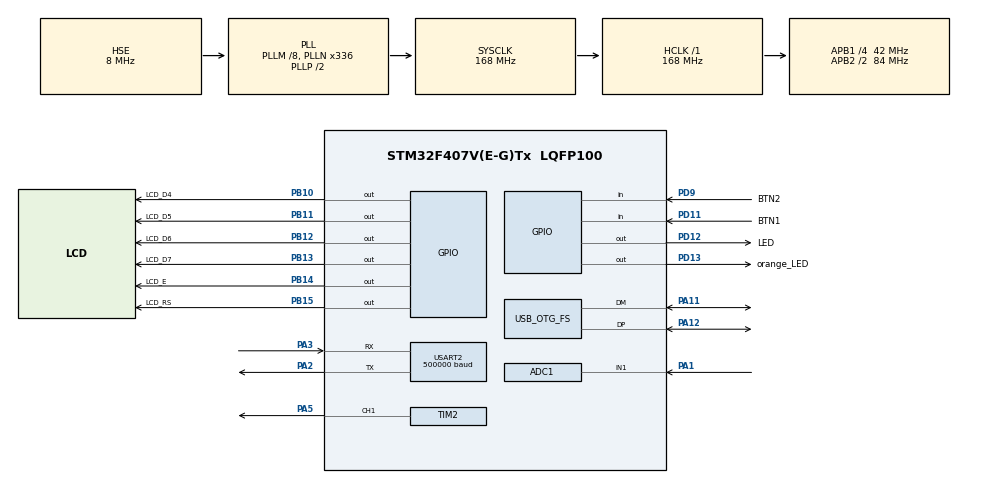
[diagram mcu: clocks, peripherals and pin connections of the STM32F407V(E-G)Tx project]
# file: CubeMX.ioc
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ADC1.Channel-1\#ChannelRegularConversion=ADC_CHANNEL_1
ADC1.NbrOfConversionFlag=1
ADC1.Rank-1\#ChannelRegularConversion=1
ADC1.SamplingTime-1\#ChannelRegularConversion=ADC_SAMPLETIME_3CYCLES
ADC1.master=1
FREERTOS.Tasks01=defaultTask,24,128,StartDefaultTask,Default,NULL,Dynamic,NULL,NULL
Mcu.Family=STM32F4
Mcu.Name=STM32F407V(E-G)Tx
Mcu.Package=LQFP100
NVIC.PriorityGroup=NVIC_PRIORITYGROUP_4
NVIC.TIM7_IRQn=true\:15\:0\:false\:false\:true\:false\:false\:true\:true
NVIC.TimeBase=TIM7_IRQn
NVIC.TimeBaseIP=TIM7
PA1.Signal=ADCx_IN1
PA11.Mode=Device_Only
PA11.Signal=USB_OTG_FS_DM
PA12.Mode=Device_Only
PA12.Signal=USB_OTG_FS_DP
PA2.Mode=Asynchronous
PA2.Signal=USART2_TX
PA3.Mode=Asynchronous
PA3.Signal=USART2_RX
PA5.Signal=S_TIM2_CH1_ETR
PB10.GPIO_Label=LCD_D4
PB10.Signal=GPIO_Output
PB11.GPIO_Label=LCD_D5
PB11.Signal=GPIO_Output
PB12.GPIO_Label=LCD_D6
PB12.Signal=GPIO_Output
PB13.GPIO_Label=LCD_D7
PB13.Signal=GPIO_Output
PB14.GPIO_Label=LCD_E
PB14.Signal=GPIO_Output
PB15.GPIO_Label=LCD_RS
PB15.Signal=GPIO_Output
PD11.GPIO_Label=BTN1
PD11.GPIO_PuPd=GPIO_PULLUP
PD11.Signal=GPIO_Input
PD12.GPIO_Label=LED
PD12.Signal=GPIO_Output
PD13.GPIO_Label=orange_LED
PD13.Signal=GPIO_Output
PD9.GPIO_Label=BTN2
PD9.GPIO_PuPd=GPIO_PULLUP
PD9.Signal=GPIO_Input
PH0-OSC_IN.Mode=HSE-External-Oscillator
PH0-OSC_IN.Signal=RCC_OSC_IN
PH1-OSC_OUT.Mode=HSE-External-Oscillator
PH1-OSC_OUT.Signal=RCC_OSC_OUT
ProjectManager.HeapSize=0x200
ProjectManager.StackSize=0x400
ProjectManager.TargetToolchain=CMake
RCC.48MHZClocksFreq_Value=48000000
RCC.AHBFreq_Value=168000000
RCC.APB1CLKDivider=RCC_HCLK_DIV4
RCC.APB1Freq_Value=42000000
RCC.APB1TimFreq_Value=84000000
RCC.APB2CLKDivider=RCC_HCLK_DIV2
RCC.APB2Freq_Value=84000000
RCC.APB2TimFreq_Value=168000000
RCC.CortexFreq_Value=168000000
RCC.HCLKFreq_Value=168000000
RCC.HSE_VALUE=8000000
RCC.HSI_VALUE=16000000
RCC.LSE_VALUE=32768
RCC.PLLM=8
RCC.PLLN=336
RCC.PLLQ=7
RCC.SYSCLKFreq_VALUE=168000000
RCC.SYSCLKSource=RCC_SYSCLKSOURCE_PLLCLK
RCC.VCOOutputFreq_Value=336000000
SH.ADCx_IN1.0=ADC1_IN1,IN1
SH.S_TIM2_CH1_ETR.0=TIM2_CH1,PWM Generation1 CH1
TIM2.AutoReloadPreload=TIM_AUTORELOAD_PRELOAD_ENABLE
TIM2.Channel-PWM\ Generation1\ CH1=TIM_CHANNEL_1
TIM2.Period=19999
TIM2.Prescaler=83
TIM3.Prescaler=83
USART2.BaudRate=500000
USART2.VirtualMode=VM_ASYNC
USB_OTG_FS.VirtualMode=Device_Only
VP_FREERTOS_VS_CMSIS_V2.Mode=CMSIS_V2
VP_SYS_VS_tim7.Mode=TIM7
VP_TIM3_VS_ClockSourceINT.Mode=Internal
board=custom

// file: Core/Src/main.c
/* USER CODE BEGIN Header */
/**
 ******************************************************************************
 * @file           : main.c
 * @brief          : Main program body
 ******************************************************************************
 * @attention
 *
 * Copyright (c) 2026 STMicroelectronics.
 * All rights reserved.
 *
 * This software is licensed under terms that can be found in the LICENSE file
 * in the root directory of this software component.
 * If no LICENSE file comes with this software, it is provided AS-IS.
 *
 ******************************************************************************
 */
/* USER CODE END Header */
#include "main.h"
#include "cmsis_os.h"

/* USER CODE BEGIN Includes */
#include "logger/itm.h"
#include "main_app.h"
#include "usb/usb_app.h"
/* USER CODE END Includes */

ADC_HandleTypeDef hadc1;

TIM_HandleTypeDef htim2;
TIM_HandleTypeDef htim3;

UART_HandleTypeDef huart2;

PCD_HandleTypeDef hpcd_USB_OTG_FS;

/* Definitions for defaultTask */
osThreadId_t defaultTaskHandle;
const osThreadAttr_t defaultTask_attributes = {
  .name = "defaultTask",
  .stack_size = 128 * 4,
  .priority = (osPriority_t) osPriorityNormal,
};

void SystemClock_Config(void);
static void MX_GPIO_Init(void);
static void MX_TIM2_Init(void);
static void MX_ADC1_Init(void);
static void MX_USB_OTG_FS_PCD_Init(void);
static void MX_USART2_UART_Init(void);
static void MX_TIM3_Init(void);
void StartDefaultTask(void *argument);

int main(void)
{

  /* MCU Configuration--------------------------------------------------------*/

  /* Reset of all peripherals, Initializes the Flash interface and the Systick. */
  HAL_Init();

  /* USER CODE BEGIN Init */
    /* FreeRTOS requires PRIGROUP = 0 so vPortValidateInterruptPriority() passes
     * before the scheduler runs vPortSetupTimerInterrupt(). On STM32F407 (4 priority
     * bits implemented) PRIGROUP 0 and NVIC_PRIORITYGROUP_4 (3) are functionally
     * identical — the lower 4 bits don't exist in hardware. */
    NVIC_SetPriorityGrouping(0);
  /* USER CODE END Init */

  /* Configure the system clock */
  SystemClock_Config();

  /* Initialize all configured peripherals */
  MX_GPIO_Init();
  MX_TIM2_Init();
  MX_ADC1_Init();
  MX_USB_OTG_FS_PCD_Init();
  MX_USART2_UART_Init();
  MX_TIM3_Init();
  /* USER CODE BEGIN 2 */
    HAL_TIM_Base_Start(&htim3);
    ITM_Init();
    usb_app_init();
  /* USER CODE END 2 */

  /* Init scheduler */
  osKernelInitialize();

  /* Create the thread(s) */
  /* creation of defaultTask */
  defaultTaskHandle = osThreadNew(StartDefaultTask, NULL, &defaultTask_attributes);

  /* USER CODE BEGIN RTOS_THREADS */
    /* add threads, ... */
    // app_init();

  /* USER CODE END RTOS_THREADS */

  /* USER CODE BEGIN RTOS_EVENTS */
    /* add events, ... */

    app_init();
  /* USER CODE END RTOS_EVENTS */

  /* Start scheduler */
  osKernelStart();

  /* We should never get here as control is now taken by the scheduler */

  /* Infinite loop */
  /* USER CODE BEGIN WHILE */
    // vTaskStartScheduler();

    while (1)
    {
    /* USER CODE END WHILE */

    }
}

void SystemClock_Config(void)
{
  RCC_OscInitTypeDef RCC_OscInitStruct = {0};
  RCC_ClkInitTypeDef RCC_ClkInitStruct = {0};

  /** Configure the main internal regulator output voltage
  */
  __HAL_RCC_PWR_CLK_ENABLE();
  __HAL_PWR_VOLTAGESCALING_CONFIG(PWR_REGULATOR_VOLTAGE_SCALE1);

  /** Initializes the RCC Oscillators according to the specified parameters
  * in the RCC_OscInitTypeDef structure.
  */
  RCC_OscInitStruct.OscillatorType = RCC_OSCILLATORTYPE_HSE;
  RCC_OscInitStruct.HSEState = RCC_HSE_ON;
  RCC_OscInitStruct.PLL.PLLState = RCC_PLL_ON;
  RCC_OscInitStruct.PLL.PLLSource = RCC_PLLSOURCE_HSE;
  RCC_OscInitStruct.PLL.PLLM = 8;
  RCC_OscInitStruct.PLL.PLLN = 336;
  RCC_OscInitStruct.PLL.PLLP = RCC_PLLP_DIV2;
  RCC_OscInitStruct.PLL.PLLQ = 7;
  if (HAL_RCC_OscConfig(&RCC_OscInitStruct) != HAL_OK)
  {
    Error_Handler();
  }

  /** Initializes the CPU, AHB and APB buses clocks
  */
  RCC_ClkInitStruct.ClockType = RCC_CLOCKTYPE_HCLK|RCC_CLOCKTYPE_SYSCLK
                              |RCC_CLOCKTYPE_PCLK1|RCC_CLOCKTYPE_PCLK2;
  RCC_ClkInitStruct.SYSCLKSource = RCC_SYSCLKSOURCE_PLLCLK;
  RCC_ClkInitStruct.AHBCLKDivider = RCC_SYSCLK_DIV1;
  RCC_ClkInitStruct.APB1CLKDivider = RCC_HCLK_DIV4;
  RCC_ClkInitStruct.APB2CLKDivider = RCC_HCLK_DIV2;

  if (HAL_RCC_ClockConfig(&RCC_ClkInitStruct, FLASH_LATENCY_5) != HAL_OK)
  {
    Error_Handler();
  }
}

static void MX_ADC1_Init(void)
{

  ADC_ChannelConfTypeDef sConfig = {0};

  /** Configure the global features of the ADC (Clock, Resolution, Data Alignment and number of conversion)
  */
  hadc1.Instance = ADC1;
  hadc1.Init.ClockPrescaler = ADC_CLOCK_SYNC_PCLK_DIV4;
  hadc1.Init.Resolution = ADC_RESOLUTION_12B;
  hadc1.Init.ScanConvMode = DISABLE;
  hadc1.Init.ContinuousConvMode = DISABLE;
  hadc1.Init.DiscontinuousConvMode = DISABLE;
  hadc1.Init.ExternalTrigConvEdge = ADC_EXTERNALTRIGCONVEDGE_NONE;
  hadc1.Init.ExternalTrigConv = ADC_SOFTWARE_START;
  hadc1.Init.DataAlign = ADC_DATAALIGN_RIGHT;
  hadc1.Init.NbrOfConversion = 1;
  hadc1.Init.DMAContinuousRequests = DISABLE;
  hadc1.Init.EOCSelection = ADC_EOC_SINGLE_CONV;
  if (HAL_ADC_Init(&hadc1) != HAL_OK)
  {
    Error_Handler();
  }

  /** Configure for the selected ADC regular channel its corresponding rank in the sequencer and its sample time.
  */
  sConfig.Channel = ADC_CHANNEL_1;
  sConfig.Rank = 1;
  sConfig.SamplingTime = ADC_SAMPLETIME_3CYCLES;
  if (HAL_ADC_ConfigChannel(&hadc1, &sConfig) != HAL_OK)
  {
    Error_Handler();
  }

}

static void MX_TIM2_Init(void)
{

  TIM_MasterConfigTypeDef sMasterConfig = {0};
  TIM_OC_InitTypeDef sConfigOC = {0};

  htim2.Instance = TIM2;
  htim2.Init.Prescaler = 83;
  htim2.Init.CounterMode = TIM_COUNTERMODE_UP;
  htim2.Init.Period = 19999;
  htim2.Init.ClockDivision = TIM_CLOCKDIVISION_DIV1;
  htim2.Init.AutoReloadPreload = TIM_AUTORELOAD_PRELOAD_ENABLE;
  if (HAL_TIM_PWM_Init(&htim2) != HAL_OK)
  {
    Error_Handler();
  }
  sMasterConfig.MasterOutputTrigger = TIM_TRGO_RESET;
  sMasterConfig.MasterSlaveMode = TIM_MASTERSLAVEMODE_DISABLE;
  if (HAL_TIMEx_MasterConfigSynchronization(&htim2, &sMasterConfig) != HAL_OK)
  {
    Error_Handler();
  }
  sConfigOC.OCMode = TIM_OCMODE_PWM1;
  sConfigOC.Pulse = 0;
  sConfigOC.OCPolarity = TIM_OCPOLARITY_HIGH;
  sConfigOC.OCFastMode = TIM_OCFAST_DISABLE;
  if (HAL_TIM_PWM_ConfigChannel(&htim2, &sConfigOC, TIM_CHANNEL_1) != HAL_OK)
  {
    Error_Handler();
  }
  HAL_TIM_MspPostInit(&htim2);

}

static void MX_TIM3_Init(void)
{

  TIM_ClockConfigTypeDef sClockSourceConfig = {0};
  TIM_MasterConfigTypeDef sMasterConfig = {0};

  htim3.Instance = TIM3;
  htim3.Init.Prescaler = 83;
  htim3.Init.CounterMode = TIM_COUNTERMODE_UP;
  htim3.Init.Period = 65535;
  htim3.Init.ClockDivision = TIM_CLOCKDIVISION_DIV1;
  htim3.Init.AutoReloadPreload = TIM_AUTORELOAD_PRELOAD_DISABLE;
  if (HAL_TIM_Base_Init(&htim3) != HAL_OK)
  {
    Error_Handler();
  }
  sClockSourceConfig.ClockSource = TIM_CLOCKSOURCE_INTERNAL;
  if (HAL_TIM_ConfigClockSource(&htim3, &sClockSourceConfig) != HAL_OK)
  {
    Error_Handler();
  }
  sMasterConfig.MasterOutputTrigger = TIM_TRGO_RESET;
  sMasterConfig.MasterSlaveMode = TIM_MASTERSLAVEMODE_DISABLE;
  if (HAL_TIMEx_MasterConfigSynchronization(&htim3, &sMasterConfig) != HAL_OK)
  {
    Error_Handler();
  }

}

static void MX_USART2_UART_Init(void)
{

  huart2.Instance = USART2;
  huart2.Init.BaudRate = 500000;
  huart2.Init.WordLength = UART_WORDLENGTH_8B;
  huart2.Init.StopBits = UART_STOPBITS_1;
  huart2.Init.Parity = UART_PARITY_NONE;
  huart2.Init.Mode = UART_MODE_TX_RX;
  huart2.Init.HwFlowCtl = UART_HWCONTROL_NONE;
  huart2.Init.OverSampling = UART_OVERSAMPLING_16;
  if (HAL_UART_Init(&huart2) != HAL_OK)
  {
    Error_Handler();
  }

}

static void MX_USB_OTG_FS_PCD_Init(void)
{

  hpcd_USB_OTG_FS.Instance = USB_OTG_FS;
  hpcd_USB_OTG_FS.Init.dev_endpoints = 4;
  hpcd_USB_OTG_FS.Init.speed = PCD_SPEED_FULL;
  hpcd_USB_OTG_FS.Init.dma_enable = DISABLE;
  hpcd_USB_OTG_FS.Init.phy_itface = PCD_PHY_EMBEDDED;
  hpcd_USB_OTG_FS.Init.Sof_enable = DISABLE;
  hpcd_USB_OTG_FS.Init.low_power_enable = DISABLE;
  hpcd_USB_OTG_FS.Init.lpm_enable = DISABLE;
  hpcd_USB_OTG_FS.Init.vbus_sensing_enable = DISABLE;
  hpcd_USB_OTG_FS.Init.use_dedicated_ep1 = DISABLE;
  if (HAL_PCD_Init(&hpcd_USB_OTG_FS) != HAL_OK)
  {
    Error_Handler();
  }

}

static void MX_GPIO_Init(void)
{
  GPIO_InitTypeDef GPIO_InitStruct = {0};

  /* GPIO Ports Clock Enable */
  __HAL_RCC_GPIOH_CLK_ENABLE();
  __HAL_RCC_GPIOA_CLK_ENABLE();
  __HAL_RCC_GPIOB_CLK_ENABLE();
  __HAL_RCC_GPIOD_CLK_ENABLE();

  /*Configure GPIO pin Output Level */
  HAL_GPIO_WritePin(GPIOB, LCD_D4_Pin|LCD_D5_Pin|LCD_D6_Pin|LCD_D7_Pin
                          |LCD_E_Pin|LCD_RS_Pin, GPIO_PIN_RESET);

  /*Configure GPIO pin Output Level */
  HAL_GPIO_WritePin(GPIOD, LED_Pin|orange_LED_Pin, GPIO_PIN_RESET);

  /*Configure GPIO pins : LCD_D4_Pin LCD_D5_Pin LCD_D6_Pin LCD_D7_Pin
                           LCD_E_Pin LCD_RS_Pin */
  GPIO_InitStruct.Pin = LCD_D4_Pin|LCD_D5_Pin|LCD_D6_Pin|LCD_D7_Pin
                          |LCD_E_Pin|LCD_RS_Pin;
  GPIO_InitStruct.Mode = GPIO_MODE_OUTPUT_PP;
  GPIO_InitStruct.Pull = GPIO_NOPULL;
  GPIO_InitStruct.Speed = GPIO_SPEED_FREQ_LOW;
  HAL_GPIO_Init(GPIOB, &GPIO_InitStruct);

  /*Configure GPIO pins : BTN2_Pin BTN1_Pin */
  GPIO_InitStruct.Pin = BTN2_Pin|BTN1_Pin;
  GPIO_InitStruct.Mode = GPIO_MODE_INPUT;
  GPIO_InitStruct.Pull = GPIO_PULLUP;
  HAL_GPIO_Init(GPIOD, &GPIO_InitStruct);

  /*Configure GPIO pins : LED_Pin orange_LED_Pin */
  GPIO_InitStruct.Pin = LED_Pin|orange_LED_Pin;
  GPIO_InitStruct.Mode = GPIO_MODE_OUTPUT_PP;
  GPIO_InitStruct.Pull = GPIO_NOPULL;
  GPIO_InitStruct.Speed = GPIO_SPEED_FREQ_LOW;
  HAL_GPIO_Init(GPIOD, &GPIO_InitStruct);

}

void StartDefaultTask(void *argument)
{
    for (;;)
    {
        osDelay(1);
    }
}

void HAL_TIM_PeriodElapsedCallback(TIM_HandleTypeDef *htim)
{
  if (htim->Instance == TIM7)
  {
    HAL_IncTick();
  }
}

void Error_Handler(void)
{
    __disable_irq();
    while (1)
    {
    }
}
